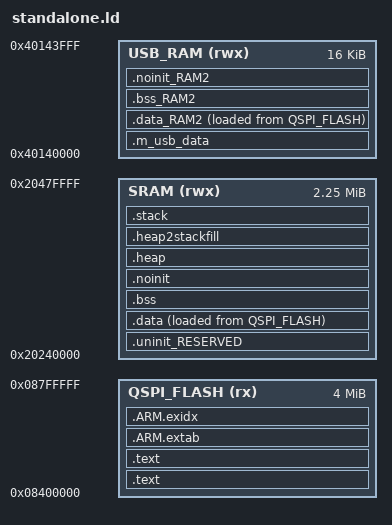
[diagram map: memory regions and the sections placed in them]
MEMORY
{
  /* Define each memory region */
  QSPI_FLASH (rx) : ORIGIN = 0x8400000, LENGTH = 0x400000 /* 4M bytes (alias Flash) */  
  SRAM (rwx) : ORIGIN = 0x20240000, LENGTH = 0x240000 /* 2.25M bytes (alias RAM) */  
  USB_RAM (rwx) : ORIGIN = 0x40140000, LENGTH = 0x4000 /* 16K bytes (alias RAM2) */  
}

PROVIDE(hardware_init_hook = 0);
PROVIDE(software_init_hook = 0);
PROVIDE(software_term_hook = 0);

ENTRY(_kernel_start)

SECTIONS
{
    /* MAIN TEXT SECTION */
    .text : ALIGN(4)
    {
        FILL(0xff)
        __vectors_start__ = ABSOLUTE(.) ;
        KEEP(*(.isr_vector))
        /* Global Section Table */
        . = ALIGN(4) ;
        __section_table_start = .;
        __data_section_table = .;
        LONG(LOADADDR(.data));
        LONG(    ADDR(.data));
        LONG(  SIZEOF(.data));
        LONG(LOADADDR(.data_RAM2));
        LONG(    ADDR(.data_RAM2));
        LONG(  SIZEOF(.data_RAM2));
        __data_section_table_end = .;
        __bss_section_table = .;
        LONG(    ADDR(.bss));
        LONG(  SIZEOF(.bss));
        LONG(    ADDR(.bss_RAM2));
        LONG(  SIZEOF(.bss_RAM2));
        __bss_section_table_end = .;
        __section_table_end = . ;
        /* End of Global Section Table */

        *(.after_vectors*)
    } > QSPI_FLASH

    .text : ALIGN(4)
    {
       *(.text*)
       *(.rodata .rodata.* .constdata .constdata.*)
       . = ALIGN(4);
    } > QSPI_FLASH
    /*
     * for exception handling/unwind - some Newlib functions (in common
     * with C++ and STDC++) use this.
     */
    .ARM.extab : ALIGN(4)
    {
        *(.ARM.extab* .gnu.linkonce.armextab.*)
    } > QSPI_FLASH

    .ARM.exidx : ALIGN(4)
    {
        __exidx_start = .;
        *(.ARM.exidx* .gnu.linkonce.armexidx.*)
        __exidx_end = .;
    } > QSPI_FLASH
 
    _etext = .;
        
 
    /* USB_RAM */
    .m_usb_data (NOLOAD) :
    {
        *(m_usb_global)
    } > USB_RAM AT> USB_RAM
    /* DATA section for USB_RAM */

    .data_RAM2 : ALIGN(4)
    {
        FILL(0xff)
        PROVIDE(__start_data_RAM2 = .) ;
        PROVIDE(__start_data_USB_RAM = .) ;
        *(.ramfunc.$RAM2)
        *(.ramfunc.$USB_RAM)
        *(.data.$RAM2)
        *(.data.$USB_RAM)
        *(.data.$RAM2.*)
        *(.data.$USB_RAM.*)
        . = ALIGN(4) ;
        PROVIDE(__end_data_RAM2 = .) ;
        PROVIDE(__end_data_USB_RAM = .) ;
     } > USB_RAM AT>QSPI_FLASH

    /* MAIN DATA SECTION */
    .uninit_RESERVED (NOLOAD) : ALIGN(4)
    {
        _start_uninit_RESERVED = .;
        KEEP(*(.bss.$RESERVED*))
       . = ALIGN(4) ;
        _end_uninit_RESERVED = .;
    } > SRAM AT> SRAM

    /* Main DATA section (SRAM) */
    .data : ALIGN(4)
    {
       FILL(0xff)
       _data = . ;
       PROVIDE(__start_data_RAM = .) ;
       PROVIDE(__start_data_SRAM = .) ;
       *(vtable)
       *(.ramfunc*)
       KEEP(*(CodeQuickAccess))
       KEEP(*(DataQuickAccess))
       *(RamFunction)
       *(.data*)
       . = ALIGN(4) ;
       _edata = . ;
       PROVIDE(__end_data_RAM = .) ;
       PROVIDE(__end_data_SRAM = .) ;
    } > SRAM AT>QSPI_FLASH

    /* BSS section for USB_RAM */
    .bss_RAM2 : ALIGN(4)
    {
       PROVIDE(__start_bss_RAM2 = .) ;
       PROVIDE(__start_bss_USB_RAM = .) ;
       *(.bss.$RAM2)
       *(.bss.$USB_RAM)
       *(.bss.$RAM2.*)
       *(.bss.$USB_RAM.*)
       . = ALIGN (. != 0 ? 4 : 1) ; /* avoid empty segment */
       PROVIDE(__end_bss_RAM2 = .) ;
       PROVIDE(__end_bss_USB_RAM = .) ;
    } > USB_RAM AT> USB_RAM

    /* MAIN BSS SECTION */
    .bss : ALIGN(4)
    {
        _bss = .;
        PROVIDE(__start_bss_RAM = .) ;
        PROVIDE(__start_bss_SRAM = .) ;
        *(.bss*)
        *(COMMON)
        . = ALIGN(4) ;
        _ebss = .;
        PROVIDE(__end_bss_RAM = .) ;
        PROVIDE(__end_bss_SRAM = .) ;
        PROVIDE(end = .);
    } > SRAM AT> SRAM

    /* NOINIT section for USB_RAM */
    .noinit_RAM2 (NOLOAD) : ALIGN(4)
    {
       PROVIDE(__start_noinit_RAM2 = .) ;
       PROVIDE(__start_noinit_USB_RAM = .) ;
       *(.noinit.$RAM2)
       *(.noinit.$USB_RAM)
       *(.noinit.$RAM2.*)
       *(.noinit.$USB_RAM.*)
       . = ALIGN(4) ;
       PROVIDE(__end_noinit_RAM2 = .) ;
       PROVIDE(__end_noinit_USB_RAM = .) ;
    } > USB_RAM AT> USB_RAM

    /* DEFAULT NOINIT SECTION */
    .noinit (NOLOAD): ALIGN(4)
    {
        _noinit = .;
        PROVIDE(__start_noinit_RAM = .) ;
        PROVIDE(__start_noinit_SRAM = .) ;
        *(.noinit*)
         . = ALIGN(4) ;
        _end_noinit = .;
       PROVIDE(__end_noinit_RAM = .) ;
       PROVIDE(__end_noinit_SRAM = .) ;        
    } > SRAM AT> SRAM

    /* Reserve and place Heap within memory map */
    _HeapSize = 0x2000;
    .heap :  ALIGN(4)
    {
        _pvHeapStart = .;
        . += _HeapSize;
        . = ALIGN(4);
        _pvHeapLimit = .;
    } > SRAM

     _StackSize = 0x2000;
     /* Reserve space in memory for Stack */
    .heap2stackfill  :
    {
        . += _StackSize;
    } > SRAM
    /* Locate actual Stack in memory map */
    .stack ORIGIN(SRAM) + LENGTH(SRAM) - _StackSize - 0:  ALIGN(4)
    {
        _vStackBase = .;
        . = ALIGN(4);
        _vStackTop = . + _StackSize;
    } > SRAM

    /* Provide basic symbols giving location and size of main text
     * block, including initial values of RW data sections. Note that
     * these will need extending to give a complete picture with
     * complex images (e.g multiple Flash banks).
     */
    _image_start = LOADADDR(.text);
    _image_end = LOADADDR(.data) + SIZEOF(.data);
    _image_size = _image_end - _image_start;

    /* Provide symbols for MIMXRT600 parts for startup code to use
     * to set image to be plain load image or XIP.
     * Config : Plain load image = false
     */
    __imghdr_loadaddress = LOADADDR(.text);
    __imghdr_imagetype = 4;
}
